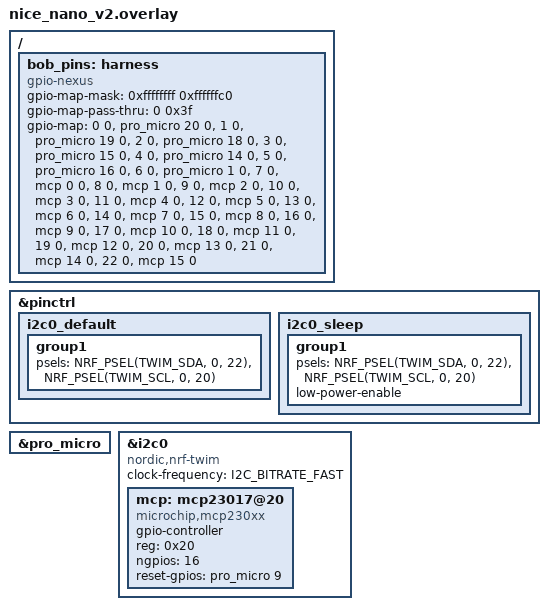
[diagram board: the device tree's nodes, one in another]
/*
 * Copyright (c) 2021 Yonatan Schachter
 *
 * SPDX-License-Identifier: Apache-2.0
 */

#include <freq.h>

&pinctrl {
    i2c0_default: i2c0_default {
        group1 {
            psels = <NRF_PSEL(TWIM_SDA, 0, 22)>,
                <NRF_PSEL(TWIM_SCL, 0, 20)>;
        };
    };

    i2c0_sleep: i2c0_sleep {
        group1 {
            psels = <NRF_PSEL(TWIM_SDA, 0, 22)>,
                <NRF_PSEL(TWIM_SCL, 0, 20)>;
            low-power-enable;
        };
    };
};

/ {
	bob_pins: harness {
		compatible = "gpio-nexus";
		#gpio-cells = <2>;
		gpio-map-mask = <0xffffffff 0xffffffc0>;
		gpio-map-pass-thru = <0 0x3f>;
		gpio-map = 
			<0 0 &pro_micro 20 0>,	/* GP */
			<1 0 &pro_micro 19 0>,	/* GP */
			<2 0 &pro_micro 18 0>,	/* GP */
			<3 0 &pro_micro 15 0>,	/* GP */
			<4 0 &pro_micro 14 0>,	/* GP */
			<5 0 &pro_micro 16 0>,	/* GP */

			<6 0 &pro_micro 1 0>,	/* GP */
			<7 0 &mcp 0 0>,	/* GP */
			<8 0 &mcp 1 0>,	/* GP */
			<9 0 &mcp 2 0>,	/* GP */
			<10 0 &mcp 3 0>,	/* GP */
			<11 0 &mcp 4 0>,	/* GP */
			<12 0 &mcp 5 0>,	/* GP */
			<13 0 &mcp 6 0>,	/* GP */
			<14 0 &mcp 7 0>,	/* GP */
			
			<15 0 &mcp 8 0>,	/* GP */
			<16 0 &mcp 9 0>,	/* GP */
			<17 0 &mcp 10 0>,	/* GP */
			<18 0 &mcp 11 0>,	/* GP */
			<19 0 &mcp 12 0>,	/* GP */
			<20 0 &mcp 13 0>,	/* GP */
			<21 0 &mcp 14 0>,	/* GP */
			<22 0 &mcp 15 0>;  /* GP */
	};

};

&pro_micro {
	status = "okay";
};

&i2c0 {
	compatible = "nordic,nrf-twim";
	clock-frequency = <I2C_BITRATE_FAST>;

	status = "okay";
    #address-cells = <1>;
    #size-cells = <0>;
    mcp: mcp23017@20 {
        compatible = "microchip,mcp230xx";
        status = "okay";
        gpio-controller;
        reg = <0x20>;
        #gpio-cells = <2>;
        ngpios = <16>;
		reset-gpios = <&pro_micro 9 0>;
    };
};
